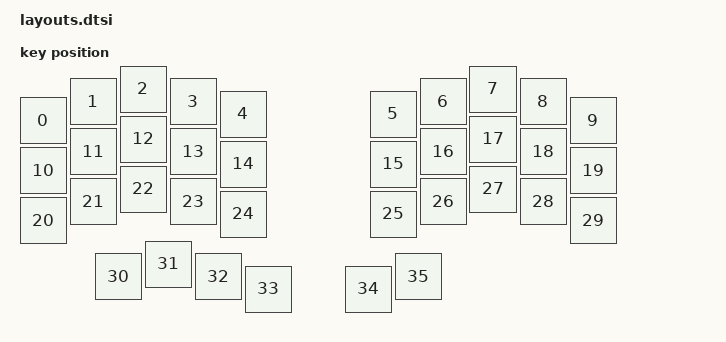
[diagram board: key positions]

#include <physical_layouts.dtsi>
/ {
    physical_layout0: physical_layout0 {
        compatible = "zmk,physical-layout";
        display-name = "Layout";
        keys
            = <&key_physical_attrs 100 100 (-50) 63 0 0 0>
			,<&key_physical_attrs 100 100 50 25 0 0 0>
			,<&key_physical_attrs 100 100 150 0 0 0 0>
			,<&key_physical_attrs 100 100 250 25 0 0 0>
			,<&key_physical_attrs 100 100 350 50 0 0 0>
			,<&key_physical_attrs 100 100 650 50 0 0 0>
			,<&key_physical_attrs 100 100 750 25 0 0 0>
			,<&key_physical_attrs 100 100 850 0 0 0 0>
			,<&key_physical_attrs 100 100 950 25 0 0 0>
			,<&key_physical_attrs 100 100 1050 63 0 0 0>
			,<&key_physical_attrs 100 100 (-50) 163 0 0 0>
			,<&key_physical_attrs 100 100 50 125 0 0 0>
			,<&key_physical_attrs 100 100 150 100 0 0 0>
			,<&key_physical_attrs 100 100 250 125 0 0 0>
			,<&key_physical_attrs 100 100 350 150 0 0 0>
			,<&key_physical_attrs 100 100 650 150 0 0 0>
			,<&key_physical_attrs 100 100 750 125 0 0 0>
			,<&key_physical_attrs 100 100 850 100 0 0 0>
			,<&key_physical_attrs 100 100 950 125 0 0 0>
			,<&key_physical_attrs 100 100 1050 163 0 0 0>
			,<&key_physical_attrs 100 100 (-50) 263 0 0 0>
			,<&key_physical_attrs 100 100 50 225 0 0 0>
			,<&key_physical_attrs 100 100 150 200 0 0 0>
			,<&key_physical_attrs 100 100 250 225 0 0 0>
			,<&key_physical_attrs 100 100 350 250 0 0 0>
			,<&key_physical_attrs 100 100 650 250 0 0 0>
			,<&key_physical_attrs 100 100 750 225 0 0 0>
			,<&key_physical_attrs 100 100 850 200 0 0 0>
			,<&key_physical_attrs 100 100 950 225 0 0 0>
			,<&key_physical_attrs 100 100 1050 263 0 0 0>
			,<&key_physical_attrs 100 100 100 375 0 0 0>
			,<&key_physical_attrs 100 100 200 350 0 0 0>
			,<&key_physical_attrs 100 100 300 375 0 0 0>
			,<&key_physical_attrs 100 100 400 400 0 0 0>
			,<&key_physical_attrs 100 100 600 400 0 0 0>
			,<&key_physical_attrs 100 100 700 375 0 0 0>
            ;
    };
};
    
